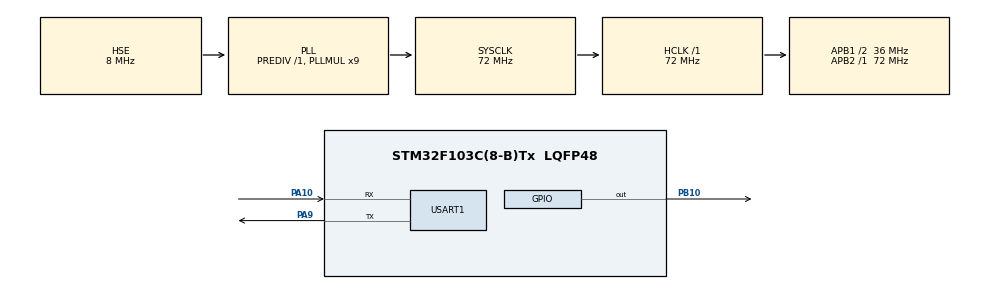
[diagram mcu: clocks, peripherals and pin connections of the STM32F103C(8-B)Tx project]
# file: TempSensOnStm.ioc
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Mcu.Family=STM32F1
Mcu.Name=STM32F103C(8-B)Tx
Mcu.Package=LQFP48
NVIC.PriorityGroup=NVIC_PRIORITYGROUP_4
NVIC.TIM3_IRQn=true\:0\:0\:false\:false\:true\:true\:true
PA10.Mode=Asynchronous
PA10.Signal=USART1_RX
PA13.Mode=Serial_Wire
PA13.Signal=SYS_JTMS-SWDIO
PA14.Mode=Serial_Wire
PA14.Signal=SYS_JTCK-SWCLK
PA9.Mode=Asynchronous
PA9.Signal=USART1_TX
PB10.GPIO_Speed=GPIO_SPEED_FREQ_HIGH
PB10.PinState=GPIO_PIN_SET
PB10.Signal=GPIO_Output
PD0-OSC_IN.Mode=HSE-External-Oscillator
PD0-OSC_IN.Signal=RCC_OSC_IN
PD1-OSC_OUT.Mode=HSE-External-Oscillator
PD1-OSC_OUT.Signal=RCC_OSC_OUT
ProjectManager.HeapSize=0x200
ProjectManager.StackSize=0x400
ProjectManager.TargetToolchain=TrueSTUDIO
RCC.AHBFreq_Value=72000000
RCC.APB1CLKDivider=RCC_HCLK_DIV2
RCC.APB1Freq_Value=36000000
RCC.APB1TimFreq_Value=72000000
RCC.APB2Freq_Value=72000000
RCC.APB2TimFreq_Value=72000000
RCC.HCLKFreq_Value=72000000
RCC.PLLMUL=RCC_PLL_MUL9
RCC.PLLSourceVirtual=RCC_PLLSOURCE_HSE
RCC.SYSCLKFreq_VALUE=72000000
RCC.SYSCLKSource=RCC_SYSCLKSOURCE_PLLCLK
RCC.USBFreq_Value=72000000
TIM3.Period=65535
TIM3.Prescaler=288
USART1.VirtualMode=VM_ASYNC
VP_TIM3_VS_ClockSourceINT.Mode=Internal
board=custom

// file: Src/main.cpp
/* USER CODE BEGIN Header */
/**
  ******************************************************************************
  * @file           : main.c
  * @brief          : Main program body
  ******************************************************************************
  * @attention
  *
  * <h2><center>&copy; Copyright (c) 2019 STMicroelectronics.
  * All rights reserved.</center></h2>
  *
  * This software component is licensed by ST under BSD 3-Clause license,
  * the "License"; You may not use this file except in compliance with the
  * License. You may obtain a copy of the License at:
  *                        opensource.org/licenses/BSD-3-Clause
  *
  ******************************************************************************
  */
/* USER CODE END Header */

#include "main.h"

/* USER CODE BEGIN Includes */
#include <DHTReader.h>
#include <Timer.h>
#include <cstring>
/* USER CODE END Includes */

UART_HandleTypeDef huart1;

void SystemClock_Config(void);
static void MX_GPIO_Init(void);
static void MX_USART1_UART_Init(void);
static void MX_TIM3_Init(void);

int main(void)
{

  /* MCU Configuration--------------------------------------------------------*/

  /* Reset of all peripherals, Initializes the Flash interface and the Systick. */
  HAL_Init();

  /* Configure the system clock */
  SystemClock_Config();

  /* Initialize all configured peripherals */
  MX_GPIO_Init();
  MX_USART1_UART_Init();
  MX_TIM3_Init();
  /* USER CODE BEGIN 2 */
  HAL_TIM_Base_Start_IT(&htim3);

  DHTReader reader(GPIOB, GPIO_PIN_10);
  /* USER CODE END 2 */

  /* Infinite loop */
  /* USER CODE BEGIN WHILE */

    char buff[64] = {0};

    while(true)
    {
    	memset(buff, 0, sizeof(buff));

    	//sensor requires delay for accurate measurement, including startup
	    HAL_Delay(2000);

	    const DHTData& data = reader.getData();

		if (data.status == DHTData::Status::Valid)
		{
			snprintf(buff, sizeof(buff), "Sample OK: %.2f *C %.2f %% H\n\r", static_cast<double>(data.temperature), static_cast<double>(data.humidity));
		}
		else if (data.status == DHTData::Status::TimeoutOnSync1)
		{
			snprintf(buff, sizeof(buff), "Read DHT11 timed out on the first step of sync\n\r");
		}
		else if (data.status == DHTData::Status::TimeoutOnSync2)
		{
			snprintf(buff, sizeof(buff), "Read DHT11 timed out on the second step of sync\n\r");
		}
		else if (data.status == DHTData::Status::TimeoutOnDataReceive)
		{
			snprintf(buff, sizeof(buff), "Read DHT11 timed out while receiving data\n\r");
		}
		else if (data.status == DHTData::Status::ChecksumFailed)
		{
			snprintf(buff, sizeof(buff), "Read DHT11 with failed checksum\n\r");
		}
		else if (data.status == DHTData::Status::Other)
		{
			snprintf(buff, sizeof(buff), "Read DHT11 failed with unknown reason\n\r");
		}

	    HAL_UART_Transmit(&huart1, reinterpret_cast<uint8_t*>(buff), sizeof(buff), 1000);
      /* USER CODE END WHILE */

    }
}

void SystemClock_Config(void)
{
  RCC_OscInitTypeDef RCC_OscInitStruct = {0};
  RCC_ClkInitTypeDef RCC_ClkInitStruct = {0};

  /** Initializes the CPU, AHB and APB busses clocks
  */
  RCC_OscInitStruct.OscillatorType = RCC_OSCILLATORTYPE_HSE;
  RCC_OscInitStruct.HSEState = RCC_HSE_ON;
  RCC_OscInitStruct.HSEPredivValue = RCC_HSE_PREDIV_DIV1;
  RCC_OscInitStruct.HSIState = RCC_HSI_ON;
  RCC_OscInitStruct.PLL.PLLState = RCC_PLL_ON;
  RCC_OscInitStruct.PLL.PLLSource = RCC_PLLSOURCE_HSE;
  RCC_OscInitStruct.PLL.PLLMUL = RCC_PLL_MUL9;
  if (HAL_RCC_OscConfig(&RCC_OscInitStruct) != HAL_OK)
  {
    Error_Handler();
  }
  /** Initializes the CPU, AHB and APB busses clocks
  */
  RCC_ClkInitStruct.ClockType = RCC_CLOCKTYPE_HCLK|RCC_CLOCKTYPE_SYSCLK
                              |RCC_CLOCKTYPE_PCLK1|RCC_CLOCKTYPE_PCLK2;
  RCC_ClkInitStruct.SYSCLKSource = RCC_SYSCLKSOURCE_PLLCLK;
  RCC_ClkInitStruct.AHBCLKDivider = RCC_SYSCLK_DIV1;
  RCC_ClkInitStruct.APB1CLKDivider = RCC_HCLK_DIV2;
  RCC_ClkInitStruct.APB2CLKDivider = RCC_HCLK_DIV1;

  if (HAL_RCC_ClockConfig(&RCC_ClkInitStruct, FLASH_LATENCY_2) != HAL_OK)
  {
    Error_Handler();
  }
}

static void MX_TIM3_Init(void)
{

	TIM_ClockConfigTypeDef sClockSourceConfig = {0};
	TIM_MasterConfigTypeDef sMasterConfig = {0};

	htim3.Instance = TIM3;
	htim3.Init.Prescaler = 288;
	htim3.Init.CounterMode = TIM_COUNTERMODE_UP;
	htim3.Init.Period = 65535;
	htim3.Init.ClockDivision = TIM_CLOCKDIVISION_DIV1;
	htim3.Init.AutoReloadPreload = TIM_AUTORELOAD_PRELOAD_DISABLE;
	if (HAL_TIM_Base_Init(&htim3) != HAL_OK)
	{
	  Error_Handler();
	}
	sClockSourceConfig.ClockSource = TIM_CLOCKSOURCE_INTERNAL;
	if (HAL_TIM_ConfigClockSource(&htim3, &sClockSourceConfig) != HAL_OK)
	{
	  Error_Handler();
	}
	sMasterConfig.MasterOutputTrigger = TIM_TRGO_RESET;
	sMasterConfig.MasterSlaveMode = TIM_MASTERSLAVEMODE_DISABLE;
	if (HAL_TIMEx_MasterConfigSynchronization(&htim3, &sMasterConfig) != HAL_OK)
	{
	  Error_Handler();
	}

}

static void MX_USART1_UART_Init(void)
{

  huart1.Instance = USART1;
  huart1.Init.BaudRate = 115200;
  huart1.Init.WordLength = UART_WORDLENGTH_8B;
  huart1.Init.StopBits = UART_STOPBITS_1;
  huart1.Init.Parity = UART_PARITY_NONE;
  huart1.Init.Mode = UART_MODE_TX_RX;
  huart1.Init.HwFlowCtl = UART_HWCONTROL_NONE;
  huart1.Init.OverSampling = UART_OVERSAMPLING_16;
  if (HAL_UART_Init(&huart1) != HAL_OK)
  {
    Error_Handler();
  }

}

static void MX_GPIO_Init(void)
{
  GPIO_InitTypeDef GPIO_InitStruct = {0};

  /* GPIO Ports Clock Enable */
  __HAL_RCC_GPIOD_CLK_ENABLE();
  __HAL_RCC_GPIOB_CLK_ENABLE();

  /*Configure GPIO pin Output Level */
  HAL_GPIO_WritePin(GPIOB, GPIO_PIN_10, GPIO_PIN_SET);

  /*Configure GPIO pin : PB10 */
  GPIO_InitStruct.Pin = GPIO_PIN_10;
  GPIO_InitStruct.Mode = GPIO_MODE_OUTPUT_PP;
  GPIO_InitStruct.Pull = GPIO_NOPULL;
  GPIO_InitStruct.Speed = GPIO_SPEED_FREQ_HIGH;
  HAL_GPIO_Init(GPIOB, &GPIO_InitStruct);

}

void Error_Handler(void)
{
}

/************************ (C) COPYRIGHT STMicroelectronics *****END OF FILE****/
